# ZB32L030 register map
Vendor: ZBit.; Series: ZB32L03X; File version: 1.0
CPU: CM0+ r1p0, little endian, no MPU, no FPU, VTOR, 2 interrupt priority bits
Registers are 32-bit, read-write, reset 0x0 unless marked. A register's access mark holds for its fields unless they carry their own. Offsets are from the block's base; [hi:lo] are bit positions; 'fields as' and 'values as' point back to an identical list.

## RCC — Reset and Clock Control
Base 0x40020000
0x00 HCLKDIV — AHB CLK Prescale
  [7:0] AHBCKDIV — System HCLK Prescale
    0=DIV_1 (Prescale 1); 1=DIV_2 (Prescale 2); 2=DIV_4 (Prescale 4); 3=DIV_6 (Prescale 6)
0x04 PCLKDIV — APB CLK Prescale
  [7:0] APBCKDIV — System PCLK Prescale
    values as HCLKDIV.AHBCKDIV
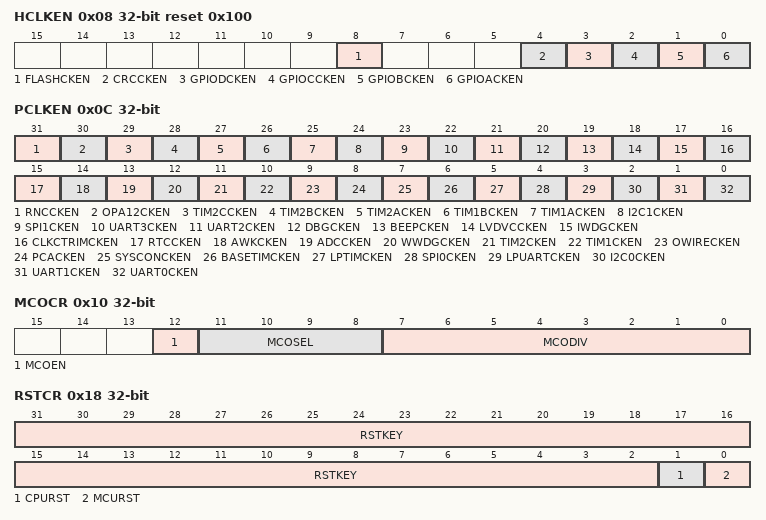
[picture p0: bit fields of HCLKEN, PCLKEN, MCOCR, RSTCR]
0x08 HCLKEN reset 0x100 — AHB Peripheral Model Clk Enable
  [8] FLASHCKEN — Flash CLK Enable
  [4] CRCCKEN — CRC CLK Enable
  [3] GPIODCKEN — GPIOD CLK Enable
  [2] GPIOCCKEN — GPIOC CLK Enable
  [1] GPIOBCKEN — GPIOB CLK Enable
  [0] GPIOACKEN — GPIOA CLK Enable
0x0C PCLKEN — APB Peripheral Model CLK Enable
  [31] RNCCKEN — RNC PCLK
  [30] OPA12CKEN — OPA1/OP2 PCLK
  [29] TIM2CCKEN — TIM2C PCLK
  [28] TIM2BCKEN — TIM2B PCLK
  [27] TIM2ACKEN — TIM2A PCLK
  [26] TIM1BCKEN — TIM1B PCLK
  [25] TIM1ACKEN — TIM1A PCLK
  [24] I2C1CKEN — I2C1 PCLK
  [23] SPI1CKEN — SPI1 PCLK
  [22] UART3CKEN — UART3 PCLK
  [21] UART2CKEN — UART2 PCLK
  [20] DBGCKEN — DBG CLK Enable
  [19] BEEPCKEN — BEEP CLK Enable
  [18] LVDVCCKEN — LVD VC CLK Enable
  [17] IWDGCKEN — IWDG CLK Enable
  [16] CLKCTRIMCKEN — CLKTRIM CLK Enable
  [15] RTCCKEN — RTC Clk Enable
  [14] AWKCKEN — ADC Clk Enable
  [13] ADCCKEN — ADC Clk Enable
  [12] WWDGCKEN — WWDG Clk Enable
  [11] TIM2CKEN — TIM2 Clk Enable
  [10] TIM1CKEN — TIM1 Clk Enable
  [9] OWIRECKEN — 1-WIRE Clk Enable
  [8] PCACKEN — PCA Clk Enable
  [7] SYSCONCKEN — System Control CLK Enable
  [6] BASETIMCKEN — BASE timer clk enable
  [5] LPTIMCKEN
  [4] SPI0CKEN — SPI0 CLK Enable
  [3] LPUARTCKEN — LPUART CLK Enable
  [2] I2C0CKEN — I2C0 CK Enable
  [1] UART1CKEN — UART1 CLK Enable
  [0] UART0CKEN — UART0 CLK Enable
0x10 MCOCR — Clock Output Control Register
  [12] MCOEN — MCO Enable
  [11:8] MCOSEL — Clock Output Source Select
    0=HIRC (HIRC clock); 1=HXT (External High Speed Clock); 2=SIRC (SIRC clock); 3=LXT (External Low Speed Clock); 4=SYSCLK (System clock); 5=HCLK (High performance Bus Clock); 8=PCLK (Peripheral clock)
  [7:0] MCODIV — HCLK Prescale
0x18 RSTCR — System Reset Control
  [31:2] RSTKEY wo — Auth Key, RSTKEY=0x156A99A6
  [1] CPURST — CUP Reset
  [0] MCURST — MCU RESET
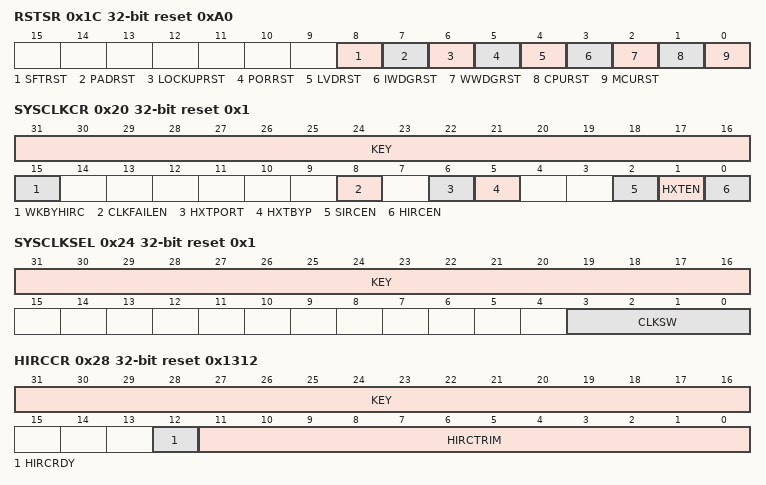
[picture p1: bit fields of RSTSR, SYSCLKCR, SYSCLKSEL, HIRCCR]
0x1C RSTSR reset 0xA0 — Reset Status
  [8] SFTRST — Cotrex-M0+ CPU Software RST FLAG
  [7] PADRST — PAD_RESET RST FLAG
  [6] LOCKUPRST — Cotrex-M0+ CPU Lockup RST FLAG
  [5] PORRST — POR RST FLAG
  [4] LVDRST — LVD RST FLAG
  [3] IWDGRST — IWDG RST FLAG
  [2] WWDGRST — WWDG RST FLAG
  [1] CPURST — CPU reset
  [0] MCURST — MCU Reset Flag
0x20 SYSCLKCR reset 0x1 — CLK Setting
  [31:16] KEY wo — Auth Key, KEY=0x5A69
  [15] WKBYHIRC — Wake-up by HIRc
  [8] CLKFAILEN — CLK FAIL Enable
  [6] HXTPORT — HXT Port Function Config
  [5] HXTBYP — HXT Bypass
  [2] SIRCEN — SIRC Enable
  [1] HXTEN — HXT Enable
  [0] HIRCEN — HIRC Enable
0x24 SYSCLKSEL reset 0x1 — System Clock Select
  [31:16] KEY wo — Auth Key, KEY=0x5A69
  [3:0] CLKSW — System Clock Source Select
    1=HIRC (HIRC clock); 2=HXT (External High Speed Clock); 4=SIRC (SIRC clock); 8=LXT (External Low Speed Clock)
0x28 HIRCCR reset 0x1312 — HIRC Control
  [31:16] KEY wo — Auth Key, KEY=0x5A69
  [12] HIRCRDY ro
  [11:0] HIRCTRIM — HIRC Trim value
    0x200=TRIMLEVEL_4M (Trim level 4MHz, bit[9]); 0x400=TRIMLEVEL_8M (Trim level 8MHz, bit[10]); 0x600=TRIMLEVEL_12M (Trim level 12MHz, bit[10,9]); 0x800=TRIMLEVEL_16M (Trim level 16MHz, bit[11]); 0xA00=TRIMLEVEL_22M (Trim level 22MHz, bit[11,9]); 0xC00=TRIMLEVEL_24M (Trim level 24MHz, bit[11,10]); 0xE00=TRIMLEVEL_MSK (Trim level bits[11:9])
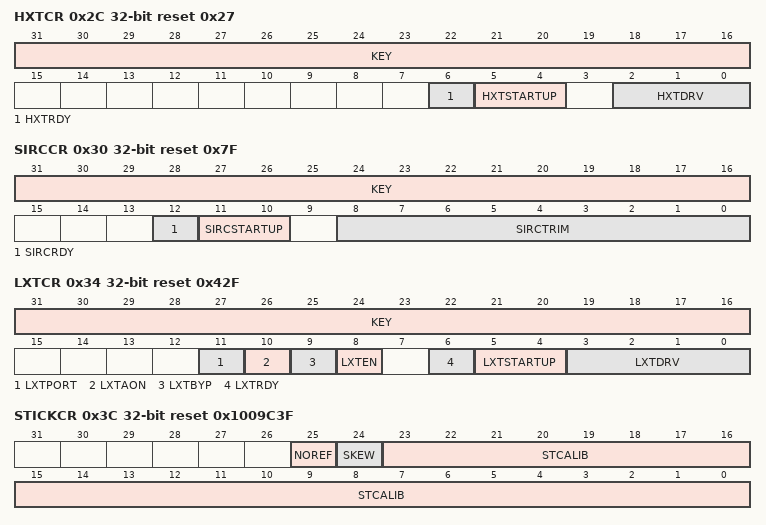
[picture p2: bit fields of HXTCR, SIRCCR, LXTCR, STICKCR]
0x2C HXTCR reset 0x27 — HXT Control
  [31:16] KEY wo — Auth Key, KEY=0x5A69
  [6] HXTRDY ro — HXT Ready
  [5:4] HXTSTARTUP — Stable cycle select
  [2:0] HXTDRV — HXT driving select
0x30 SIRCCR reset 0x7F — SIRC Control
  [31:16] KEY wo — Auth Key, KEY=0x5A69
  [12] SIRCRDY ro — SIRC ready
  [11:10] SIRCSTARTUP — Stable cycle select
    0=4CYCLE; 1=16CYCLE; 2=64CYCLE; 3=256CYCLE
  [8:0] SIRCTRIM — SIRC Trim value
0x34 LXTCR reset 0x42F — LXT Control
  [31:16] KEY wo — Auth Key, KEY=0x5A69
  [11] LXTPORT — X32K_IN/X32K_OUT Alternate function
  [10] LXTAON
  [9] LXTBYP — LXT Bypass
  [8] LXTEN — LXT enable
  [6] LXTRDY ro — RDY
  [5:4] LXTSTARTUP — Stable cycle select
  [3:0] LXTDRV — LXT driving select
0x38 IRQLATENCY — M0 IRQ latency
  [7:0] IRQLATENCY
0x3C STICKCR reset 0x1009C3F — SysTick Timer Circle Adjust
  [25] NOREF — SysTick No Ref
  [24] SKEW — 10ms STCALIB skew
  [23:0] STCALIB — SysTick 10ms calibration value
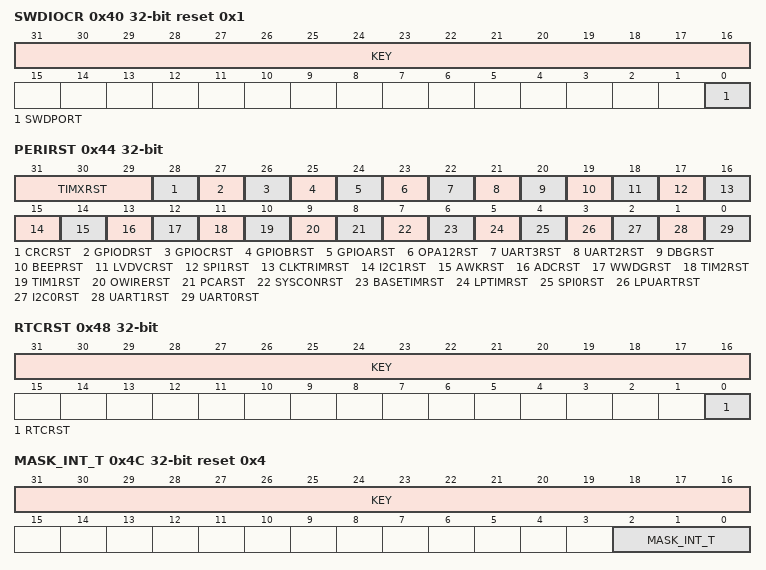
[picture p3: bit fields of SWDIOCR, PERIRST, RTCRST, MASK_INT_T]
0x40 SWDIOCR reset 0x1 — SWDIO Endpoint Function Select
  [31:16] KEY wo — Auth Key, KEY=0x5A69
  [0] SWDPORT — SWD enable
0x44 PERIRST — Peripheral Model Control
  [31:29] TIMXRST — TIMx reset
    1=TIM1ARST (Timer1A reset); 2=TIM1BRST (Timer1B reset); 3=TIM2ARST (Timer2A reset); 4=TIM2BRST (Timer2B reset); 5=TIM2CRST (Timer2C reset)
  [28] CRCRST — CRC reset
  [27] GPIODRST — GPIOD reset
  [26] GPIOCRST — GPIOC reset
  [25] GPIOBRST — GPIOB reset
  [24] GPIOARST — GPIOA reset
  [23] OPA12RST — OPA12 reset
  [22] UART3RST — UART3 reset
  [21] UART2RST — UART2 reset
  [20] DBGRST — DBG reset
  [19] BEEPRST — BEEP reset
  [18] LVDVCRST — LVDVC reset
  [17] SPI1RST — SPI1 reset
  [16] CLKTRIMRST — CLKTRIM reset
  [15] I2C1RST — I2C1 reset
  [14] AWKRST — AWK reset
  [13] ADCRST — ADC reset
  [12] WWDGRST — WWDG reset
  [11] TIM2RST — TIM2 reset
  [10] TIM1RST — TIM1 reset
  [9] OWIRERST — OWIRE reset
  [8] PCARST — PCA reset
  [7] SYSCONRST — SYSCON reset
  [6] BASETIMRST — Base Timer10/11 reset
  [5] LPTIMRST — LPTIM reset
  [4] SPI0RST — SPI0 reset
  [3] LPUARTRST — LPUART reset
  [2] I2C0RST — I2C0 reset
  [1] UART1RST — UART1 reset
  [0] UART0RST — UART0 reset
0x48 RTCRST — RTC Control
  [31:16] KEY wo — Auth Key, KEY=0x5A69
  [0] RTCRST
0x4C MASK_INT_T reset 0x4 — mask interrupt time
  [31:16] KEY wo — Auth Key, KEY=0x5A69
  [2:0] MASK_INT_T — mask interrupt time when enter deep-sleep
    0=1_6_MS; 1=1_4_MS; 2=1_2_MS; 3=1_0_MS; 4=0_8_MS; 5=0_6_MS; 6=0_4_MS; 7=0_2_MS
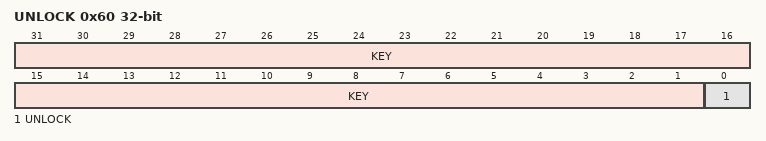
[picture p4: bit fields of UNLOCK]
0x60 UNLOCK — Register Protect
  [31:1] KEY wo — Auth Key, KEY=0x2AD5334C
  [0] UNLOCK
